# MIMXRT1011 register map
Vendor: nxp.com; File version: 1.0
CPU: CM7 r0p1, little endian, MPU, FPU, VTOR, 4 interrupt priority bits
Registers are 32-bit, read-write, reset 0x0 unless marked. A register's access mark holds for its fields unless they carry their own. Offsets are from the block's base; [hi:lo] are bit positions.

## IOMUXC (part 1 of 2)
Base 0x401F8000; register names take the prefix IOMUXC_
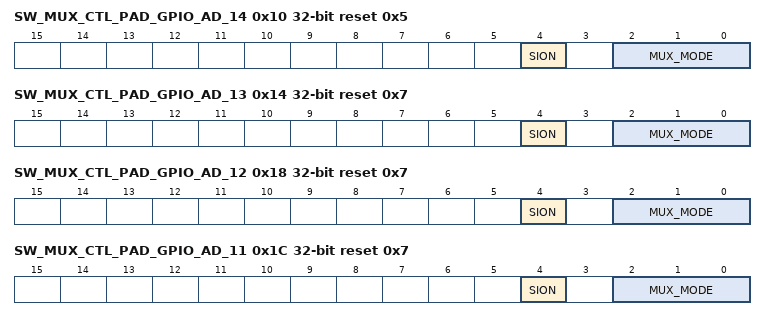
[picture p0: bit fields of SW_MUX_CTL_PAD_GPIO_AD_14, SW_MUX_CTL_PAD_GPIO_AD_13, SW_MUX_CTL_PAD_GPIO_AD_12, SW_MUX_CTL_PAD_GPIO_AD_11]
0x10 SW_MUX_CTL_PAD_GPIO_AD_14 reset 0x5 — SW_MUX_CTL_PAD_GPIO_AD_14 SW MUX Control Register
  [4] SION — Software Input On Field.
    0=DISABLED (Input Path is determined by functionality); 1=ENABLED (Force input path of pad GPIO_AD_14)
  [2:0] MUX_MODE — MUX Mode Select Field.
    0=ALT0 (Select mux mode: ALT0 mux port: LPI2C1_SCL of instance: LPI2C1); 1=ALT1 (Select mux mode: ALT1 mux port: LPUART3_CTS_B of instance: LPUART3); 2=ALT2 (Select mux mode: ALT2 mux port: KPP_COL00 of instance: KPP); 3=ALT3 (Select mux mode: ALT3 mux port: LPUART4_CTS_B of instance: LPUART4); 4=ALT4 (Select mux mode: ALT4 mux port: FLEXIO1_IO26 of instance: FLEXIO1); 5=ALT5 (Select mux mode: ALT5 mux port: GPIOMUX_IO28 of instance: GPIOMUX); 6=ALT6 (Select mux mode: ALT6 mux port: REF_CLK_24M of instance: XTAL OSC); 7=ALT7 (Select mux mode: ALT7 mux port: XBAR1_INOUT02 of instance: XBAR1)
0x14 SW_MUX_CTL_PAD_GPIO_AD_13 reset 0x7 — SW_MUX_CTL_PAD_GPIO_AD_13 SW MUX Control Register
  [4] SION — Software Input On Field.
    0=DISABLED (Input Path is determined by functionality); 1=ENABLED (Force input path of pad GPIO_AD_13)
  [2:0] MUX_MODE — MUX Mode Select Field.
    0=ALT0 (Select mux mode: ALT0 mux port: LPI2C1_SDA of instance: LPI2C1); 1=ALT1 (Select mux mode: ALT1 mux port: LPUART3_RTS_B of instance: LPUART3); 2=ALT2 (Select mux mode: ALT2 mux port: KPP_ROW00 of instance: KPP); 3=ALT3 (Select mux mode: ALT3 mux port: LPUART4_RTS_B of instance: LPUART4); 4=ALT4 (Select mux mode: ALT4 mux port: FLEXIO1_IO25 of instance: FLEXIO1); 5=ALT5 (Select mux mode: ALT5 mux port: GPIOMUX_IO27 of instance: GPIOMUX); 6=ALT6 (Select mux mode: ALT6 mux port: ARM_NMI of instance: NMI_GLUE); 7=ALT7 (Select mux mode: ALT7 mux port: JTAG_TMS of instance: JTAG)
0x18 SW_MUX_CTL_PAD_GPIO_AD_12 reset 0x7 — SW_MUX_CTL_PAD_GPIO_AD_12 SW MUX Control Register
  [4] SION — Software Input On Field.
    0=DISABLED (Input Path is determined by functionality); 1=ENABLED (Force input path of pad GPIO_AD_12)
  [2:0] MUX_MODE — MUX Mode Select Field.
    0=ALT0 (Select mux mode: ALT0 mux port: LPSPI2_SCK of instance: LPSPI2); 1=ALT1 (Select mux mode: ALT1 mux port: FLEXPWM1_PWM0_X of instance: FLEXPWM1); 2=ALT2 (Select mux mode: ALT2 mux port: KPP_COL01 of instance: KPP); 3=ALT3 (Select mux mode: ALT3 mux port: PIT_TRIGGER01 of instance: PIT); 4=ALT4 (Select mux mode: ALT4 mux port: FLEXIO1_IO24 of instance: FLEXIO1); 5=ALT5 (Select mux mode: ALT5 mux port: GPIOMUX_IO26 of instance: GPIOMUX); 6=ALT6 (Select mux mode: ALT6 mux port: USB_OTG1_PWR of instance: USB); 7=ALT7 (Select mux mode: ALT7 mux port: JTAG_TCK of instance: JTAG)
0x1C SW_MUX_CTL_PAD_GPIO_AD_11 reset 0x7 — SW_MUX_CTL_PAD_GPIO_AD_11 SW MUX Control Register
  [4] SION — Software Input On Field.
    0=DISABLED (Input Path is determined by functionality); 1=ENABLED (Force input path of pad GPIO_AD_11)
  [2:0] MUX_MODE — MUX Mode Select Field.
    0=ALT0 (Select mux mode: ALT0 mux port: LPSPI2_PCS0 of instance: LPSPI2); 1=ALT1 (Select mux mode: ALT1 mux port: FLEXPWM1_PWM1_X of instance: FLEXPWM1); 2=ALT2 (Select mux mode: ALT2 mux port: KPP_ROW01 of instance: KPP); 3=ALT3 (Select mux mode: ALT3 mux port: PIT_TRIGGER02 of instance: PIT); 4=ALT4 (Select mux mode: ALT4 mux port: FLEXIO1_IO23 of instance: FLEXIO1); 5=ALT5 (Select mux mode: ALT5 mux port: GPIOMUX_IO25 of instance: GPIOMUX); 6=ALT6 (Select mux mode: ALT6 mux port: WDOG1_B of instance: WDOG1); 7=ALT7 (Select mux mode: ALT7 mux port: JTAG_MOD of instance: JTAG)
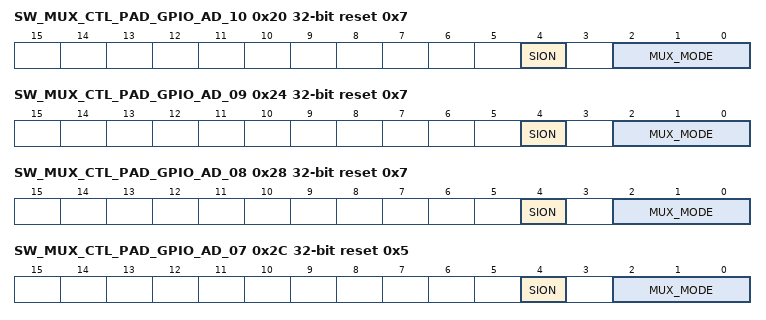
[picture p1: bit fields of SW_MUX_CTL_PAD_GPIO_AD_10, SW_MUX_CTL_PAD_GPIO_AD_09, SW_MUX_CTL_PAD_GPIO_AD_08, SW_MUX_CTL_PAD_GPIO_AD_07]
0x20 SW_MUX_CTL_PAD_GPIO_AD_10 reset 0x7 — SW_MUX_CTL_PAD_GPIO_AD_10 SW MUX Control Register
  [4] SION — Software Input On Field.
    0=DISABLED (Input Path is determined by functionality); 1=ENABLED (Force input path of pad GPIO_AD_10)
  [2:0] MUX_MODE — MUX Mode Select Field.
    0=ALT0 (Select mux mode: ALT0 mux port: LPSPI2_SDO of instance: LPSPI2); 1=ALT1 (Select mux mode: ALT1 mux port: FLEXPWM1_PWM2_X of instance: FLEXPWM1); 2=ALT2 (Select mux mode: ALT2 mux port: KPP_COL02 of instance: KPP); 3=ALT3 (Select mux mode: ALT3 mux port: PIT_TRIGGER03 of instance: PIT); 4=ALT4 (Select mux mode: ALT4 mux port: FLEXIO1_IO22 of instance: FLEXIO1); 5=ALT5 (Select mux mode: ALT5 mux port: GPIOMUX_IO24 of instance: GPIOMUX); 6=ALT6 (Select mux mode: ALT6 mux port: USB_OTG1_ID of instance: anatop); 7=ALT7 (Select mux mode: ALT7 mux port: JTAG_TDI of instance: JTAG)
0x24 SW_MUX_CTL_PAD_GPIO_AD_09 reset 0x7 — SW_MUX_CTL_PAD_GPIO_AD_09 SW MUX Control Register
  [4] SION — Software Input On Field.
    0=DISABLED (Input Path is determined by functionality); 1=ENABLED (Force input path of pad GPIO_AD_09)
  [2:0] MUX_MODE — MUX Mode Select Field.
    0=ALT0 (Select mux mode: ALT0 mux port: LPSPI2_SDI of instance: LPSPI2); 1=ALT1 (Select mux mode: ALT1 mux port: FLEXPWM1_PWM3_X of instance: FLEXPWM1); 2=ALT2 (Select mux mode: ALT2 mux port: KPP_ROW02 of instance: KPP); 3=ALT3 (Select mux mode: ALT3 mux port: ARM_TRACE_SWO of instance: cm7_mxrt); 4=ALT4 (Select mux mode: ALT4 mux port: FLEXIO1_IO21 of instance: FLEXIO1); 5=ALT5 (Select mux mode: ALT5 mux port: GPIOMUX_IO23 of instance: GPIOMUX); 6=ALT6 (Select mux mode: ALT6 mux port: REF_CLK_32K of instance: XTAL OSC); 7=ALT7 (Select mux mode: ALT7 mux port: JTAG_TDO of instance: JTAG)
0x28 SW_MUX_CTL_PAD_GPIO_AD_08 reset 0x7 — SW_MUX_CTL_PAD_GPIO_AD_08 SW MUX Control Register
  [4] SION — Software Input On Field.
    0=DISABLED (Input Path is determined by functionality); 1=ENABLED (Force input path of pad GPIO_AD_08)
  [2:0] MUX_MODE — MUX Mode Select Field.
    0=ALT0 (Select mux mode: ALT0 mux port: LPI2C2_SCL of instance: LPI2C2); 1=ALT1 (Select mux mode: ALT1 mux port: LPUART3_TXD of instance: LPUART3); 2=ALT2 (Select mux mode: ALT2 mux port: ARM_CM7_TXEV of instance: cm7_mxrt); 3=ALT3 (Select mux mode: ALT3 mux port: LPUART2_CTS_B of instance: LPUART2); 4=ALT4 (Select mux mode: ALT4 mux port: GPT2_COMPARE3 of instance: GPT2); 5=ALT5 (Select mux mode: ALT5 mux port: GPIOMUX_IO22 of instance: GPIOMUX); 6=ALT6 (Select mux mode: ALT6 mux port: EWM_OUT_B of instance: EWM); 7=ALT7 (Select mux mode: ALT7 mux port: JTAG_TRSTB of instance: JTAG)
0x2C SW_MUX_CTL_PAD_GPIO_AD_07 reset 0x5 — SW_MUX_CTL_PAD_GPIO_AD_07 SW MUX Control Register
  [4] SION — Software Input On Field.
    0=DISABLED (Input Path is determined by functionality); 1=ENABLED (Force input path of pad GPIO_AD_07)
  [2:0] MUX_MODE — MUX Mode Select Field.
    0=ALT0 (Select mux mode: ALT0 mux port: LPI2C2_SDA of instance: LPI2C2); 1=ALT1 (Select mux mode: ALT1 mux port: LPUART3_RXD of instance: LPUART3); 2=ALT2 (Select mux mode: ALT2 mux port: ARM_CM7_RXEV of instance: cm7_mxrt); 3=ALT3 (Select mux mode: ALT3 mux port: LPUART2_RTS_B of instance: LPUART2); 4=ALT4 (Select mux mode: ALT4 mux port: GPT2_CAPTURE2 of instance: GPT2); 5=ALT5 (Select mux mode: ALT5 mux port: GPIOMUX_IO21 of instance: GPIOMUX); 6=ALT6 (Select mux mode: ALT6 mux port: OCOTP_FUSE_LATCHED of instance: OCOTP); 7=ALT7 (Select mux mode: ALT7 mux port: XBAR1_INOUT03 of instance: XBAR1)
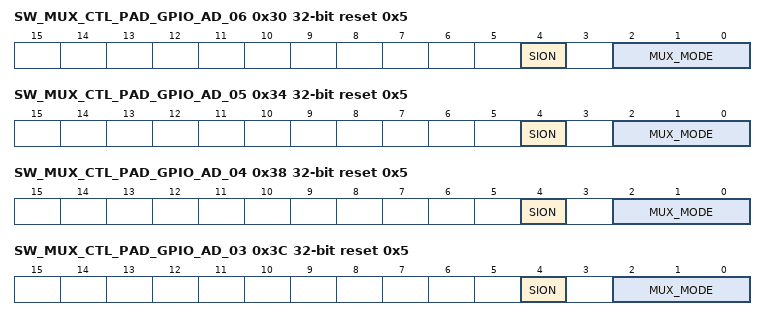
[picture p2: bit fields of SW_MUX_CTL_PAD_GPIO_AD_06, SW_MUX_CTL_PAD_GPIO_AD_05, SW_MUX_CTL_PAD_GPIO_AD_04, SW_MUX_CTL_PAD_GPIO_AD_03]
0x30 SW_MUX_CTL_PAD_GPIO_AD_06 reset 0x5 — SW_MUX_CTL_PAD_GPIO_AD_06 SW MUX Control Register
  [4] SION — Software Input On Field.
    0=DISABLED (Input Path is determined by functionality); 1=ENABLED (Force input path of pad GPIO_AD_06)
  [2:0] MUX_MODE — MUX Mode Select Field.
    0=ALT0 (Select mux mode: ALT0 mux port: LPSPI1_SCK of instance: LPSPI1); 1=ALT1 (Select mux mode: ALT1 mux port: PIT_TRIGGER00 of instance: PIT); 2=ALT2 (Select mux mode: ALT2 mux port: FLEXPWM1_PWM3_A of instance: FLEXPWM1); 3=ALT3 (Select mux mode: ALT3 mux port: KPP_COL01 of instance: KPP); 4=ALT4 (Select mux mode: ALT4 mux port: GPT2_COMPARE2 of instance: GPT2); 5=ALT5 (Select mux mode: ALT5 mux port: GPIOMUX_IO20 of instance: GPIOMUX); 6=ALT6 (Select mux mode: ALT6 mux port: LPI2C1_HREQ of instance: LPI2C1)
0x34 SW_MUX_CTL_PAD_GPIO_AD_05 reset 0x5 — SW_MUX_CTL_PAD_GPIO_AD_05 SW MUX Control Register
  [4] SION — Software Input On Field.
    0=DISABLED (Input Path is determined by functionality); 1=ENABLED (Force input path of pad GPIO_AD_05)
  [2:0] MUX_MODE — MUX Mode Select Field.
    0=ALT0 (Select mux mode: ALT0 mux port: LPSPI1_PCS0 of instance: LPSPI1); 1=ALT1 (Select mux mode: ALT1 mux port: PIT_TRIGGER01 of instance: PIT); 2=ALT2 (Select mux mode: ALT2 mux port: FLEXPWM1_PWM3_B of instance: FLEXPWM1); 3=ALT3 (Select mux mode: ALT3 mux port: KPP_ROW01 of instance: KPP); 4=ALT4 (Select mux mode: ALT4 mux port: GPT2_CAPTURE1 of instance: GPT2); 5=ALT5 (Select mux mode: ALT5 mux port: GPIOMUX_IO19 of instance: GPIOMUX)
0x38 SW_MUX_CTL_PAD_GPIO_AD_04 reset 0x5 — SW_MUX_CTL_PAD_GPIO_AD_04 SW MUX Control Register
  [4] SION — Software Input On Field.
    0=DISABLED (Input Path is determined by functionality); 1=ENABLED (Force input path of pad GPIO_AD_04)
  [2:0] MUX_MODE — MUX Mode Select Field.
    0=ALT0 (Select mux mode: ALT0 mux port: LPSPI1_SDO of instance: LPSPI1); 1=ALT1 (Select mux mode: ALT1 mux port: PIT_TRIGGER02 of instance: PIT); 2=ALT2 (Select mux mode: ALT2 mux port: FLEXPWM1_PWM2_A of instance: FLEXPWM1); 3=ALT3 (Select mux mode: ALT3 mux port: KPP_COL02 of instance: KPP); 4=ALT4 (Select mux mode: ALT4 mux port: GPT2_COMPARE1 of instance: GPT2); 5=ALT5 (Select mux mode: ALT5 mux port: GPIOMUX_IO18 of instance: GPIOMUX); 6=ALT6 (Select mux mode: ALT6 mux port: SNVS_VIO_5_CTL of instance: snvs_hp)
0x3C SW_MUX_CTL_PAD_GPIO_AD_03 reset 0x5 — SW_MUX_CTL_PAD_GPIO_AD_03 SW MUX Control Register
  [4] SION — Software Input On Field.
    0=DISABLED (Input Path is determined by functionality); 1=ENABLED (Force input path of pad GPIO_AD_03)
  [2:0] MUX_MODE — MUX Mode Select Field.
    0=ALT0 (Select mux mode: ALT0 mux port: LPSPI1_SDI of instance: LPSPI1); 1=ALT1 (Select mux mode: ALT1 mux port: PIT_TRIGGER03 of instance: PIT); 2=ALT2 (Select mux mode: ALT2 mux port: FLEXPWM1_PWM2_B of instance: FLEXPWM1); 3=ALT3 (Select mux mode: ALT3 mux port: KPP_ROW02 of instance: KPP); 4=ALT4 (Select mux mode: ALT4 mux port: GPT2_CLK of instance: GPT2); 5=ALT5 (Select mux mode: ALT5 mux port: GPIOMUX_IO17 of instance: GPIOMUX); 6=ALT6 (Select mux mode: ALT6 mux port: SNVS_VIO_5_B of instance: snvs_hp); 7=ALT7 (Select mux mode: ALT7 mux port: JTAG_DE_B of instance: JTAG)
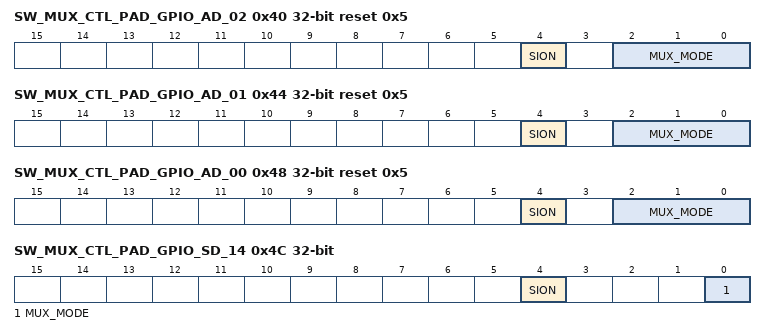
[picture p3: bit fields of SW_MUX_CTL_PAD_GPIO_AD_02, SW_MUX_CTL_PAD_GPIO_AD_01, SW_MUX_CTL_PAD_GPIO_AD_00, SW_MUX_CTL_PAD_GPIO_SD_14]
0x40 SW_MUX_CTL_PAD_GPIO_AD_02 reset 0x5 — SW_MUX_CTL_PAD_GPIO_AD_02 SW MUX Control Register
  [4] SION — Software Input On Field.
    0=DISABLED (Input Path is determined by functionality); 1=ENABLED (Force input path of pad GPIO_AD_02)
  [2:0] MUX_MODE — MUX Mode Select Field.
    0=ALT0 (Select mux mode: ALT0 mux port: LPUART4_TXD of instance: LPUART4); 1=ALT1 (Select mux mode: ALT1 mux port: LPSPI1_PCS1 of instance: LPSPI1); 2=ALT2 (Select mux mode: ALT2 mux port: WDOG2_B of instance: WDOG2); 3=ALT3 (Select mux mode: ALT3 mux port: LPI2C2_SCL of instance: LPI2C2); 4=ALT4 (Select mux mode: ALT4 mux port: MQS_RIGHT of instance: MQS); 5=ALT5 (Select mux mode: ALT5 mux port: GPIOMUX_IO16 of instance: GPIOMUX); 7=ALT7 (Select mux mode: ALT7 mux port: ARM_TRACE_CLK of instance: cm7_mxrt)
0x44 SW_MUX_CTL_PAD_GPIO_AD_01 reset 0x5 — SW_MUX_CTL_PAD_GPIO_AD_01 SW MUX Control Register
  [4] SION — Software Input On Field.
    0=DISABLED (Input Path is determined by functionality); 1=ENABLED (Force input path of pad GPIO_AD_01)
  [2:0] MUX_MODE — MUX Mode Select Field.
    0=ALT0 (Select mux mode: ALT0 mux port: LPUART4_RXD of instance: LPUART4); 1=ALT1 (Select mux mode: ALT1 mux port: LPSPI2_PCS1 of instance: LPSPI2); 2=ALT2 (Select mux mode: ALT2 mux port: WDOG1_ANY of instance: WDOG1); 3=ALT3 (Select mux mode: ALT3 mux port: LPI2C2_SDA of instance: LPI2C2); 4=ALT4 (Select mux mode: ALT4 mux port: MQS_LEFT of instance: MQS); 5=ALT5 (Select mux mode: ALT5 mux port: GPIOMUX_IO15 of instance: GPIOMUX); 6=ALT6 (Select mux mode: ALT6 mux port: USB_OTG1_OC of instance: USB); 7=ALT7 (Select mux mode: ALT7 mux port: ARM_TRACE_SWO of instance: cm7_mxrt)
0x48 SW_MUX_CTL_PAD_GPIO_AD_00 reset 0x5 — SW_MUX_CTL_PAD_GPIO_AD_00 SW MUX Control Register
  [4] SION — Software Input On Field.
    0=DISABLED (Input Path is determined by functionality); 1=ENABLED (Force input path of pad GPIO_AD_00)
  [2:0] MUX_MODE — MUX Mode Select Field.
    0=ALT0 (Select mux mode: ALT0 mux port: LPUART2_TXD of instance: LPUART2); 1=ALT1 (Select mux mode: ALT1 mux port: LPSPI1_PCS2 of instance: LPSPI1); 2=ALT2 (Select mux mode: ALT2 mux port: KPP_COL03 of instance: KPP); 3=ALT3 (Select mux mode: ALT3 mux port: USB_OTG1_PWR of instance: USB); 4=ALT4 (Select mux mode: ALT4 mux port: FLEXIO1_IO20 of instance: FLEXIO1); 5=ALT5 (Select mux mode: ALT5 mux port: GPIOMUX_IO14 of instance: GPIOMUX); 6=ALT6 (Select mux mode: ALT6 mux port: ARM_NMI of instance: NMI_GLUE); 7=ALT7 (Select mux mode: ALT7 mux port: ARM_TRACE0 of instance: cm7_mxrt)
0x4C SW_MUX_CTL_PAD_GPIO_SD_14 — SW_MUX_CTL_PAD_GPIO_SD_14 SW MUX Control Register
  [4] SION — Software Input On Field.
    0=DISABLED (Input Path is determined by functionality); 1=ENABLED (Force input path of pad GPIO_SD_14)
  [0] MUX_MODE — MUX Mode Select Field.
    0=ALT0 (Select mux mode: ALT0 mux port: FLEXSPI_A_DQS of instance: FLEXSPI); 1=ALT1 (Select mux mode: ALT1 mux port: FLEXSPI_B_DQS of instance: FLEXSPI)
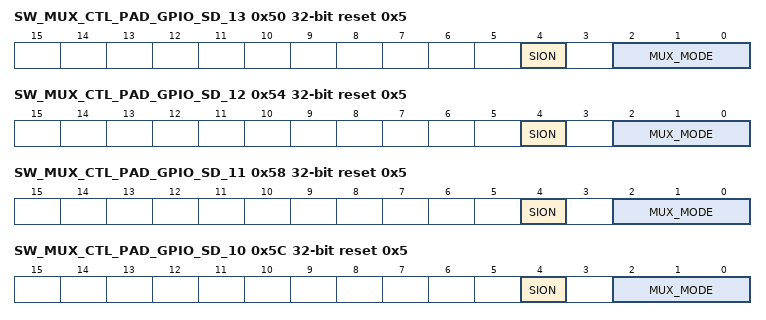
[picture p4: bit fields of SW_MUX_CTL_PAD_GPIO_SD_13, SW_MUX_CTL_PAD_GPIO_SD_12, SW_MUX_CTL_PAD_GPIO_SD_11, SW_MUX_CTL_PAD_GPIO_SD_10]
0x50 SW_MUX_CTL_PAD_GPIO_SD_13 reset 0x5 — SW_MUX_CTL_PAD_GPIO_SD_13 SW MUX Control Register
  [4] SION — Software Input On Field.
    0=DISABLED (Input Path is determined by functionality); 1=ENABLED (Force input path of pad GPIO_SD_13)
  [2:0] MUX_MODE — MUX Mode Select Field.
    0=ALT0 (Select mux mode: ALT0 mux port: FLEXSPI_B_SCLK of instance: FLEXSPI); 1=ALT1 (Select mux mode: ALT1 mux port: SAI3_RX_BCLK of instance: SAI3); 2=ALT2 (Select mux mode: ALT2 mux port: ARM_CM7_TXEV of instance: cm7_mxrt); 3=ALT3 (Select mux mode: ALT3 mux port: CCM_PMIC_RDY of instance: CCM); 4=ALT4 (Select mux mode: ALT4 mux port: FLEXIO1_IO19 of instance: FLEXIO1); 5=ALT5 (Select mux mode: ALT5 mux port: GPIO2_IO13 of instance: GPIO2); 6=ALT6 (Select mux mode: ALT6 mux port: SRC_BT_CFG03 of instance: SRC)
0x54 SW_MUX_CTL_PAD_GPIO_SD_12 reset 0x5 — SW_MUX_CTL_PAD_GPIO_SD_12 SW MUX Control Register
  [4] SION — Software Input On Field.
    0=DISABLED (Input Path is determined by functionality); 1=ENABLED (Force input path of pad GPIO_SD_12)
  [2:0] MUX_MODE — MUX Mode Select Field.
    0=ALT0 (Select mux mode: ALT0 mux port: FLEXSPI_A_DQS of instance: FLEXSPI); 1=ALT1 (Select mux mode: ALT1 mux port: LPSPI2_PCS0 of instance: LPSPI2); 2=ALT2 (Select mux mode: ALT2 mux port: LPUART1_TXD of instance: LPUART1); 4=ALT4 (Select mux mode: ALT4 mux port: FLEXIO1_IO18 of instance: FLEXIO1); 5=ALT5 (Select mux mode: ALT5 mux port: GPIO2_IO12 of instance: GPIO2); 6=ALT6 (Select mux mode: ALT6 mux port: WDOG2_RST_B_DEB of instance: WDOG2)
0x58 SW_MUX_CTL_PAD_GPIO_SD_11 reset 0x5 — SW_MUX_CTL_PAD_GPIO_SD_11 SW MUX Control Register
  [4] SION — Software Input On Field.
    0=DISABLED (Input Path is determined by functionality); 1=ENABLED (Force input path of pad GPIO_SD_11)
  [2:0] MUX_MODE — MUX Mode Select Field.
    0=ALT0 (Select mux mode: ALT0 mux port: FLEXSPI_A_DATA3 of instance: FLEXSPI); 1=ALT1 (Select mux mode: ALT1 mux port: LPSPI2_SCK of instance: LPSPI2); 2=ALT2 (Select mux mode: ALT2 mux port: LPUART1_RXD of instance: LPUART1); 4=ALT4 (Select mux mode: ALT4 mux port: FLEXIO1_IO17 of instance: FLEXIO1); 5=ALT5 (Select mux mode: ALT5 mux port: GPIO2_IO11 of instance: GPIO2); 6=ALT6 (Select mux mode: ALT6 mux port: WDOG1_RST_B_DEB of instance: WDOG1)
0x5C SW_MUX_CTL_PAD_GPIO_SD_10 reset 0x5 — SW_MUX_CTL_PAD_GPIO_SD_10 SW MUX Control Register
  [4] SION — Software Input On Field.
    0=DISABLED (Input Path is determined by functionality); 1=ENABLED (Force input path of pad GPIO_SD_10)
  [2:0] MUX_MODE — MUX Mode Select Field.
    0=ALT0 (Select mux mode: ALT0 mux port: FLEXSPI_A_SCLK of instance: FLEXSPI); 1=ALT1 (Select mux mode: ALT1 mux port: LPSPI2_SDO of instance: LPSPI2); 2=ALT2 (Select mux mode: ALT2 mux port: LPUART2_TXD of instance: LPUART2); 4=ALT4 (Select mux mode: ALT4 mux port: FLEXIO1_IO16 of instance: FLEXIO1); 5=ALT5 (Select mux mode: ALT5 mux port: GPIO2_IO10 of instance: GPIO2)
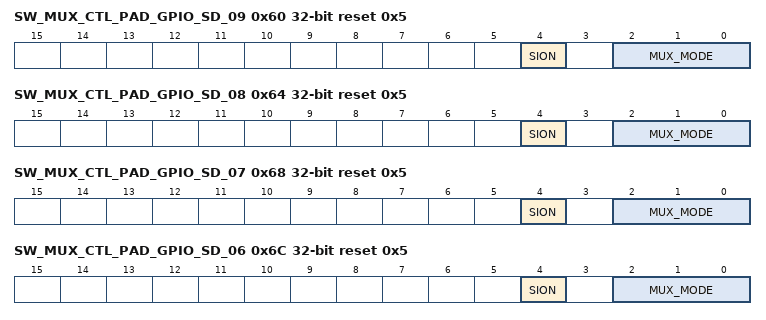
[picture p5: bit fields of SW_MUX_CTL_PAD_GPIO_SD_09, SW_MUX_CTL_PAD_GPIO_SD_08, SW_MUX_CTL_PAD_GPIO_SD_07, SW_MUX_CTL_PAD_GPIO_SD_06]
0x60 SW_MUX_CTL_PAD_GPIO_SD_09 reset 0x5 — SW_MUX_CTL_PAD_GPIO_SD_09 SW MUX Control Register
  [4] SION — Software Input On Field.
    0=DISABLED (Input Path is determined by functionality); 1=ENABLED (Force input path of pad GPIO_SD_09)
  [2:0] MUX_MODE — MUX Mode Select Field.
    0=ALT0 (Select mux mode: ALT0 mux port: FLEXSPI_A_DATA0 of instance: FLEXSPI); 1=ALT1 (Select mux mode: ALT1 mux port: LPSPI2_SDI of instance: LPSPI2); 2=ALT2 (Select mux mode: ALT2 mux port: LPUART2_RXD of instance: LPUART2); 4=ALT4 (Select mux mode: ALT4 mux port: FLEXIO1_IO15 of instance: FLEXIO1); 5=ALT5 (Select mux mode: ALT5 mux port: GPIO2_IO09 of instance: GPIO2)
0x64 SW_MUX_CTL_PAD_GPIO_SD_08 reset 0x5 — SW_MUX_CTL_PAD_GPIO_SD_08 SW MUX Control Register
  [4] SION — Software Input On Field.
    0=DISABLED (Input Path is determined by functionality); 1=ENABLED (Force input path of pad GPIO_SD_08)
  [2:0] MUX_MODE — MUX Mode Select Field.
    0=ALT0 (Select mux mode: ALT0 mux port: FLEXSPI_A_DATA2 of instance: FLEXSPI); 1=ALT1 (Select mux mode: ALT1 mux port: LPI2C2_SCL of instance: LPI2C2); 2=ALT2 (Select mux mode: ALT2 mux port: LPSPI1_SCK of instance: LPSPI1); 4=ALT4 (Select mux mode: ALT4 mux port: FLEXIO1_IO14 of instance: FLEXIO1); 5=ALT5 (Select mux mode: ALT5 mux port: GPIO2_IO08 of instance: GPIO2)
0x68 SW_MUX_CTL_PAD_GPIO_SD_07 reset 0x5 — SW_MUX_CTL_PAD_GPIO_SD_07 SW MUX Control Register
  [4] SION — Software Input On Field.
    0=DISABLED (Input Path is determined by functionality); 1=ENABLED (Force input path of pad GPIO_SD_07)
  [2:0] MUX_MODE — MUX Mode Select Field.
    0=ALT0 (Select mux mode: ALT0 mux port: FLEXSPI_A_DATA1 of instance: FLEXSPI); 1=ALT1 (Select mux mode: ALT1 mux port: LPI2C2_SDA of instance: LPI2C2); 2=ALT2 (Select mux mode: ALT2 mux port: LPSPI1_PCS0 of instance: LPSPI1); 4=ALT4 (Select mux mode: ALT4 mux port: FLEXIO1_IO13 of instance: FLEXIO1); 5=ALT5 (Select mux mode: ALT5 mux port: GPIO2_IO07 of instance: GPIO2)
0x6C SW_MUX_CTL_PAD_GPIO_SD_06 reset 0x5 — SW_MUX_CTL_PAD_GPIO_SD_06 SW MUX Control Register
  [4] SION — Software Input On Field.
    0=DISABLED (Input Path is determined by functionality); 1=ENABLED (Force input path of pad GPIO_SD_06)
  [2:0] MUX_MODE — MUX Mode Select Field.
    0=ALT0 (Select mux mode: ALT0 mux port: FLEXSPI_A_SS0_B of instance: FLEXSPI); 1=ALT1 (Select mux mode: ALT1 mux port: LPI2C1_SCL of instance: LPI2C1); 2=ALT2 (Select mux mode: ALT2 mux port: LPSPI1_SDO of instance: LPSPI1); 4=ALT4 (Select mux mode: ALT4 mux port: FLEXIO1_IO12 of instance: FLEXIO1); 5=ALT5 (Select mux mode: ALT5 mux port: GPIO2_IO06 of instance: GPIO2)
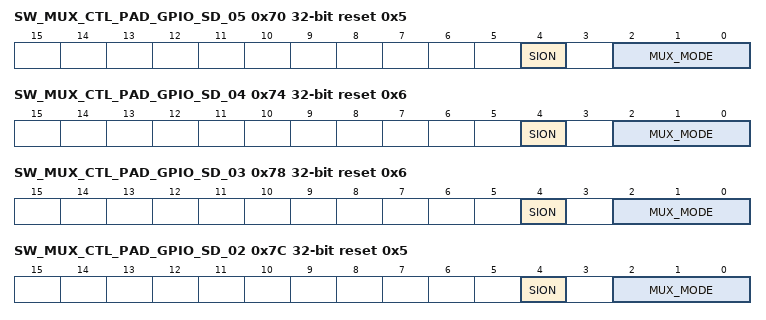
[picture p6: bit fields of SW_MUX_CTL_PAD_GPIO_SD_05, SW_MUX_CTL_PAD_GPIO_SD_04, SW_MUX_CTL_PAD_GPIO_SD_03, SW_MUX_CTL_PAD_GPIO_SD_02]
0x70 SW_MUX_CTL_PAD_GPIO_SD_05 reset 0x5 — SW_MUX_CTL_PAD_GPIO_SD_05 SW MUX Control Register
  [4] SION — Software Input On Field.
    0=DISABLED (Input Path is determined by functionality); 1=ENABLED (Force input path of pad GPIO_SD_05)
  [2:0] MUX_MODE — MUX Mode Select Field.
    0=ALT0 (Select mux mode: ALT0 mux port: FLEXSPI_A_SS1_B of instance: FLEXSPI); 1=ALT1 (Select mux mode: ALT1 mux port: LPI2C1_SDA of instance: LPI2C1); 2=ALT2 (Select mux mode: ALT2 mux port: LPSPI1_SDI of instance: LPSPI1); 4=ALT4 (Select mux mode: ALT4 mux port: FLEXIO1_IO11 of instance: FLEXIO1); 5=ALT5 (Select mux mode: ALT5 mux port: GPIO2_IO05 of instance: GPIO2)
0x74 SW_MUX_CTL_PAD_GPIO_SD_04 reset 0x6 — SW_MUX_CTL_PAD_GPIO_SD_04 SW MUX Control Register
  [4] SION — Software Input On Field.
    0=DISABLED (Input Path is determined by functionality); 1=ENABLED (Force input path of pad GPIO_SD_04)
  [2:0] MUX_MODE — MUX Mode Select Field.
    0=ALT0 (Select mux mode: ALT0 mux port: FLEXSPI_B_DATA03 of instance: FLEXSPI); 1=ALT1 (Select mux mode: ALT1 mux port: SAI3_RX_SYNC of instance: SAI3); 2=ALT2 (Select mux mode: ALT2 mux port: FLEXPWM1_PWM1_A of instance: FLEXPWM1); 3=ALT3 (Select mux mode: ALT3 mux port: CCM_WAIT of instance: CCM); 4=ALT4 (Select mux mode: ALT4 mux port: FLEXIO1_IO10 of instance: FLEXIO1); 5=ALT5 (Select mux mode: ALT5 mux port: GPIO2_IO04 of instance: GPIO2); 6=ALT6 (Select mux mode: ALT6 mux port: SRC_BOOT_MODE00 of instance: SRC)
0x78 SW_MUX_CTL_PAD_GPIO_SD_03 reset 0x6 — SW_MUX_CTL_PAD_GPIO_SD_03 SW MUX Control Register
  [4] SION — Software Input On Field.
    0=DISABLED (Input Path is determined by functionality); 1=ENABLED (Force input path of pad GPIO_SD_03)
  [2:0] MUX_MODE — MUX Mode Select Field.
    0=ALT0 (Select mux mode: ALT0 mux port: FLEXSPI_B_DATA00 of instance: FLEXSPI); 1=ALT1 (Select mux mode: ALT1 mux port: SAI3_RX_DATA of instance: SAI3); 2=ALT2 (Select mux mode: ALT2 mux port: FLEXPWM1_PWM1_B of instance: FLEXPWM1); 3=ALT3 (Select mux mode: ALT3 mux port: CCM_REF_EN_B of instance: CCM); 4=ALT4 (Select mux mode: ALT4 mux port: FLEXIO1_IO09 of instance: FLEXIO1); 5=ALT5 (Select mux mode: ALT5 mux port: GPIO2_IO03 of instance: GPIO2); 6=ALT6 (Select mux mode: ALT6 mux port: SRC_BOOT_MODE01 of instance: SRC)
0x7C SW_MUX_CTL_PAD_GPIO_SD_02 reset 0x5 — SW_MUX_CTL_PAD_GPIO_SD_02 SW MUX Control Register
  [4] SION — Software Input On Field.
    0=DISABLED (Input Path is determined by functionality); 1=ENABLED (Force input path of pad GPIO_SD_02)
  [2:0] MUX_MODE — MUX Mode Select Field.
    0=ALT0 (Select mux mode: ALT0 mux port: FLEXSPI_B_DATA02 of instance: FLEXSPI); 1=ALT1 (Select mux mode: ALT1 mux port: SAI3_TX_DATA of instance: SAI3); 2=ALT2 (Select mux mode: ALT2 mux port: FLEXPWM1_PWM0_A of instance: FLEXPWM1); 3=ALT3 (Select mux mode: ALT3 mux port: CCM_CLKO1 of instance: CCM); 4=ALT4 (Select mux mode: ALT4 mux port: FLEXIO1_IO08 of instance: FLEXIO1); 5=ALT5 (Select mux mode: ALT5 mux port: GPIO2_IO02 of instance: GPIO2); 6=ALT6 (Select mux mode: ALT6 mux port: SRC_BT_CFG00 of instance: SRC)
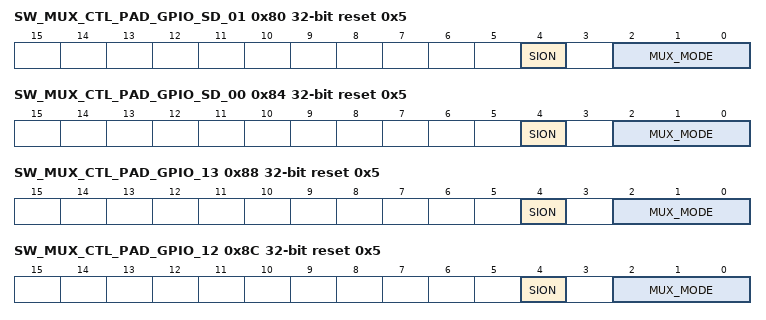
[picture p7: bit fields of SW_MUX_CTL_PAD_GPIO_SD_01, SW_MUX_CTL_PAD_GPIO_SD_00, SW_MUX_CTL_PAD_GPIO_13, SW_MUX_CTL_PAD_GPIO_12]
0x80 SW_MUX_CTL_PAD_GPIO_SD_01 reset 0x5 — SW_MUX_CTL_PAD_GPIO_SD_01 SW MUX Control Register
  [4] SION — Software Input On Field.
    0=DISABLED (Input Path is determined by functionality); 1=ENABLED (Force input path of pad GPIO_SD_01)
  [2:0] MUX_MODE — MUX Mode Select Field.
    0=ALT0 (Select mux mode: ALT0 mux port: FLEXSPI_B_DATA01 of instance: FLEXSPI); 1=ALT1 (Select mux mode: ALT1 mux port: SAI3_TX_BCLK of instance: SAI3); 2=ALT2 (Select mux mode: ALT2 mux port: FLEXPWM1_PWM0_B of instance: FLEXPWM1); 3=ALT3 (Select mux mode: ALT3 mux port: CCM_CLKO2 of instance: CCM); 4=ALT4 (Select mux mode: ALT4 mux port: FLEXIO1_IO07 of instance: FLEXIO1); 5=ALT5 (Select mux mode: ALT5 mux port: GPIO2_IO01 of instance: GPIO2); 6=ALT6 (Select mux mode: ALT6 mux port: SRC_BT_CFG01 of instance: SRC)
0x84 SW_MUX_CTL_PAD_GPIO_SD_00 reset 0x5 — SW_MUX_CTL_PAD_GPIO_SD_00 SW MUX Control Register
  [4] SION — Software Input On Field.
    0=DISABLED (Input Path is determined by functionality); 1=ENABLED (Force input path of pad GPIO_SD_00)
  [2:0] MUX_MODE — MUX Mode Select Field.
    0=ALT0 (Select mux mode: ALT0 mux port: FLEXSPI_B_SS0_B of instance: FLEXSPI); 1=ALT1 (Select mux mode: ALT1 mux port: SAI3_TX_SYNC of instance: SAI3); 2=ALT2 (Select mux mode: ALT2 mux port: ARM_CM7_RXEV of instance: cm7_mxrt); 3=ALT3 (Select mux mode: ALT3 mux port: CCM_STOP of instance: CCM); 4=ALT4 (Select mux mode: ALT4 mux port: FLEXIO1_IO06 of instance: FLEXIO1); 5=ALT5 (Select mux mode: ALT5 mux port: GPIO2_IO00 of instance: GPIO2); 6=ALT6 (Select mux mode: ALT6 mux port: SRC_BT_CFG02 of instance: SRC)
0x88 SW_MUX_CTL_PAD_GPIO_13 reset 0x5 — SW_MUX_CTL_PAD_GPIO_13 SW MUX Control Register
  [4] SION — Software Input On Field.
    0=DISABLED (Input Path is determined by functionality); 1=ENABLED (Force input path of pad GPIO_13)
  [2:0] MUX_MODE — MUX Mode Select Field.
    0=ALT0 (Select mux mode: ALT0 mux port: LPUART2_RXD of instance: LPUART2); 1=ALT1 (Select mux mode: ALT1 mux port: LPSPI2_PCS2 of instance: LPSPI2); 2=ALT2 (Select mux mode: ALT2 mux port: KPP_ROW03 of instance: KPP); 3=ALT3 (Select mux mode: ALT3 mux port: USB_OTG1_ID of instance: anatop); 4=ALT4 (Select mux mode: ALT4 mux port: FLEXIO1_IO05 of instance: FLEXIO1); 5=ALT5 (Select mux mode: ALT5 mux port: GPIOMUX_IO13 of instance: GPIOMUX); 6=ALT6 (Select mux mode: ALT6 mux port: SPDIF_LOCK of instance: SPDIF); 7=ALT7 (Select mux mode: ALT7 mux port: ARM_TRACE1 of instance: cm7_mxrt)
0x8C SW_MUX_CTL_PAD_GPIO_12 reset 0x5 — SW_MUX_CTL_PAD_GPIO_12 SW MUX Control Register
  [4] SION — Software Input On Field.
    0=DISABLED (Input Path is determined by functionality); 1=ENABLED (Force input path of pad GPIO_12)
  [2:0] MUX_MODE — MUX Mode Select Field.
    0=ALT0 (Select mux mode: ALT0 mux port: LPUART3_TXD of instance: LPUART3); 1=ALT1 (Select mux mode: ALT1 mux port: LPI2C1_SCL of instance: LPI2C1); 2=ALT2 (Select mux mode: ALT2 mux port: KPP_COL00 of instance: KPP); 3=ALT3 (Select mux mode: ALT3 mux port: USB_OTG1_OC of instance: USB); 4=ALT4 (Select mux mode: ALT4 mux port: FLEXIO1_IO04 of instance: FLEXIO1); 5=ALT5 (Select mux mode: ALT5 mux port: GPIOMUX_IO12 of instance: GPIOMUX); 6=ALT6 (Select mux mode: ALT6 mux port: SPDIF_EXT_CLK of instance: SPDIF); 7=ALT7 (Select mux mode: ALT7 mux port: ARM_TRACE2 of instance: cm7_mxrt)
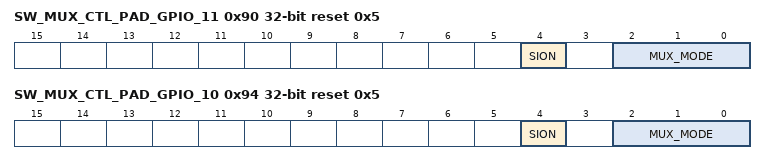
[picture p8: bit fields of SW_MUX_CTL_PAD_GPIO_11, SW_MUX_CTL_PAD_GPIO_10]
0x90 SW_MUX_CTL_PAD_GPIO_11 reset 0x5 — SW_MUX_CTL_PAD_GPIO_11 SW MUX Control Register
  [4] SION — Software Input On Field.
    0=DISABLED (Input Path is determined by functionality); 1=ENABLED (Force input path of pad GPIO_11)
  [2:0] MUX_MODE — MUX Mode Select Field.
    0=ALT0 (Select mux mode: ALT0 mux port: LPUART3_RXD of instance: LPUART3); 1=ALT1 (Select mux mode: ALT1 mux port: LPI2C1_SDA of instance: LPI2C1); 2=ALT2 (Select mux mode: ALT2 mux port: KPP_ROW00 of instance: KPP); 3=ALT3 (Select mux mode: ALT3 mux port: FLEXSPI_B_SS1_B of instance: FLEXSPI); 4=ALT4 (Select mux mode: ALT4 mux port: FLEXIO1_IO03 of instance: FLEXIO1); 5=ALT5 (Select mux mode: ALT5 mux port: GPIOMUX_IO11 of instance: GPIOMUX); 6=ALT6 (Select mux mode: ALT6 mux port: SPDIF_OUT of instance: SPDIF); 7=ALT7 (Select mux mode: ALT7 mux port: ARM_TRACE3 of instance: cm7_mxrt)
0x94 SW_MUX_CTL_PAD_GPIO_10 reset 0x5 — SW_MUX_CTL_PAD_GPIO_10 SW MUX Control Register
  [4] SION — Software Input On Field.
    0=DISABLED (Input Path is determined by functionality); 1=ENABLED (Force input path of pad GPIO_10)
  [2:0] MUX_MODE — MUX Mode Select Field.
    0=ALT0 (Select mux mode: ALT0 mux port: LPUART1_TXD of instance: LPUART1); 1=ALT1 (Select mux mode: ALT1 mux port: LPI2C1_HREQ of instance: LPI2C1); 2=ALT2 (Select mux mode: ALT2 mux port: EWM_OUT_B of instance: EWM); 3=ALT3 (Select mux mode: ALT3 mux port: LPI2C2_SCL of instance: LPI2C2); 4=ALT4 (Select mux mode: ALT4 mux port: FLEXIO1_IO02 of instance: FLEXIO1); 5=ALT5 (Select mux mode: ALT5 mux port: GPIOMUX_IO10 of instance: GPIOMUX); 6=ALT6 (Select mux mode: ALT6 mux port: SPDIF_IN of instance: SPDIF)
